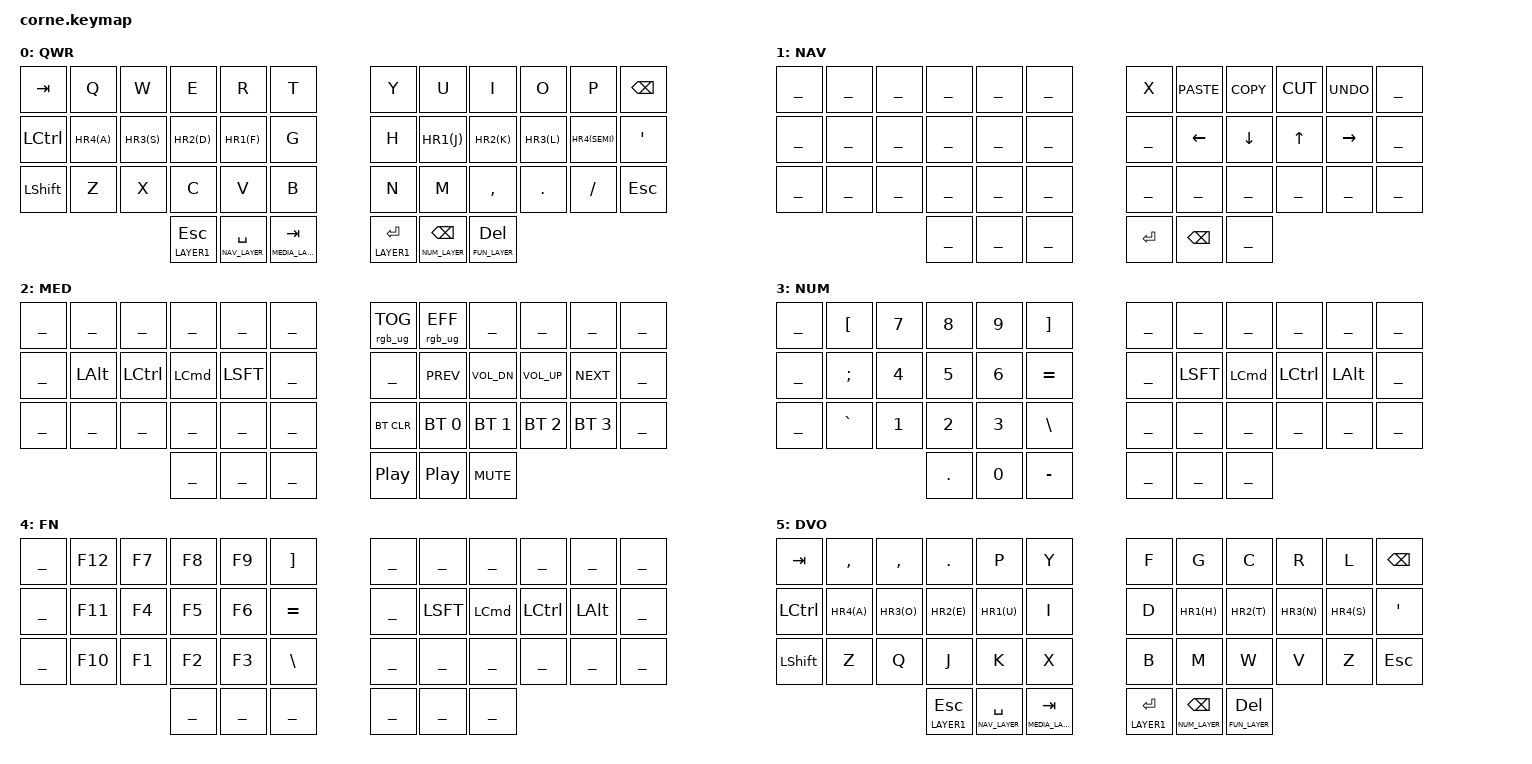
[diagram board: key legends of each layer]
/*
 * some ideas from https://github.com/rastasheep/zmk-config/blob/master/config/corne.keymap
 * and https://github.com/kkga/zmk-config-Corne-ish-Zen/blob/main/config/corne-ish_zen.keymap
 * https://github.com/manna-harbour/miryoku/tree/master/docs/reference
 * SPDX-License-Identifier: MIT
 */

#include <behaviors.dtsi>
#include <dt-bindings/zmk/keys.h>
#include <dt-bindings/zmk/bt.h>
#include <dt-bindings/zmk/rgb.h>
#include "helper.h"


&sk {
  release-after-ms = <STICKY_KEY_TIMEOUT>;
};

&caps_word {
  continue-list = <UNDERSCORE MINUS BACKSPACE N1 N2 N3 N4 N5 N6 N7 N8 N9 N0 KP_N1 KP_N2 KP_N3 KP_N4 KP_N5 KP_N6 KP_N7 KP_N8 KP_N9 KP_N0>;
};


#define HYP LS(LC(LA(LGUI)))
#define HYPER(key) LS(LC(LA(LG(key))))


#define LAYER0 0
#define LAYER1 1
#define LAYER2 2
#define LAYER3 3
#define LAYER4 4
#define LAYER5 5
#define LAYER6 6
#define LAYER7 7
#define LAYER8 8


#define QWERTY_LAYER 0
#define NAV_LAYER 1
#define MEDIA_LAYER 2
#define NUM_LAYER 3
#define FUN_LAYER 4

// thumbs
#define TH1 &mo_tap LAYER1 ESC
#define TH2 &mo_tap NAV_LAYER SPACE
#define TH3 &mo_tap MEDIA_LAYER TAB
#define TH4 &mo_tap LAYER1 RET  
#define TH5 &mo_tap NUM_LAYER BSPC
#define TH6 &mo_tap FUN_LAYER DEL


// HomeRowMod (right hand) - Shift / Cmd / Ctrl / Alt
#define HR1(KEY) &am LSFT KEY
#define HR2(KEY) &am LCMD KEY
#define HR3(KEY) &am LCTRL KEY
#define HR4(KEY) &am LALT KEY

#define HR1_ &kp LSFT 
#define HR2_ &kp LCMD 
#define HR3_ &kp LCTRL 
#define HR4_ &kp LALT 

/ {
    behaviors {
      am: alpha_mods {
          compatible = "zmk,behavior-hold-tap";
          label = "alpha mods";
          #binding-cells = <2>;
          tapping-term-ms = <240>;
          quick-tap-ms = <180>;
          flavor = "tap-preferred";
          bindings = <&kp>, <&kp>;
          // compatible = "zmk,behavior-hold-tap";
          // label = "POSITIONAL_HOLD_TAP";
          // #binding-cells = <2>;
          // flavor = "tap-unless-interrupted";
          // tapping-term-ms = <100>;                        // <---[[produces tap if held longer than tapping-term-ms]]
          // quick-tap-ms = <200>;
          // bindings = <&kp>, <&kp>;
          // hold-trigger-key-positions = <5 6 7 8 9 10>;    // <---[[right-hand keys]]
      };

      // Easy alt-tab with alt+space thumb using mod-morphs
      spctab: space_tab {
          compatible = "zmk,behavior-mod-morph";
          label = "SPC_TAB";
          #binding-cells = <0>;
          bindings = <&kp SPACE>, <&kp TAB>;
          mods = <MOD_LALT>;
      };

      skq: sticky_key_quick_release {
          compatible = "zmk,behavior-sticky-key";
          label = "STICKY_KEY_QUICK_RELEASE";
          #binding-cells = <1>;
          bindings = <&kp>;
          quick-release;
          release-after-ms = <STICKY_KEY_TIMEOUT>;
      };

      // Use hold-tap to enable rolling sticky keys:
      // https://github.com/zmkfirmware/zmk/issues/829#issuecomment-979864774
      nk: not_so_sticky_key {
          compatible = "zmk,behavior-hold-tap";
          label = "NOT_SO_STICKY_KEY";
          #binding-cells = <2>;
          tapping_term_ms = <240>;
          flavor = "tap-preferred";
          bindings = <&kp>, <&sk>;
      };

      // A hold-tap that activates without delay (like `&mo`)
      mo_tap: mo_with_tap {
          compatible = "zmk,behavior-hold-tap";
          label = "MO_WITH_TAP";
          #binding-cells = <2>;
          tapping_term_ms = <0>;
          retro-tap;
          flavor = "hold-preferred";
          bindings = <&mo>, <&kp>;
      };   
    };
        keymap {
                compatible = "zmk,keymap";
// Keyboard layout
// ╭─────────────┬─────────────┬─────────────┬─────────────┬─────────────┬─────────────╮   ╭─────────────┬─────────────┬─────────────┬─────────────┬─────────────┬─────────────╮
// ├─────────────┼─────────────┼─────────────┼─────────────┼─────────────┼─────────────┤   ├─────────────┼─────────────┼─────────────┼─────────────┼─────────────┼─────────────┤
// ├─────────────┼─────────────┼─────────────┼─────────────┼─────────────┼─────────────┤   ├─────────────┼─────────────┼─────────────┼─────────────┼─────────────┼─────────────┤
// ╰─────────────┴─────────────┴─────────────┼─────────────┼─────────────┼─────────────┤   ├─────────────┼─────────────┼─────────────┼─────────────┴─────────────┴─────────────╯
//                                           ╰─────────────┴─────────────┴─────────────╯   ╰─────────────┴─────────────┴─────────────╯



base_layer {
    label = "QWR";
    bindings = <
// ╭─────────────┬─────────────┬─────────────┬─────────────┬─────────────┬─────────────╮      ╭─────────────┬─────────────┬─────────────┬─────────────┬─────────────┬─────────────╮
     &kp TAB         &kp Q        &kp W          &kp E          &kp R         &kp T                &kp Y       &kp U          &kp I         &kp O          &kp P       &kp BSPC
// ├─────────────┼─────────────┼─────────────┼─────────────┼─────────────┼─────────────┤      ├─────────────┼─────────────┼─────────────┼─────────────┼─────────────┼─────────────┤
     &kp LCTRL      HR4(A)         HR3(S)        HR2(D)         HR1(F)        &kp G                &kp H         HR1(J)       HR2(K)         HR3(L)      HR4(SEMI)     &kp SQT
// ├─────────────┼─────────────┼─────────────┼─────────────┼─────────────┼─────────────┤      ├─────────────┼─────────────┼─────────────┼─────────────┼─────────────┼─────────────┤
     &kp LSHFT       &kp Z         &kp X         &kp C           &kp V       &kp B                 &kp N        &kp M        &kp COMMA      &kp DOT       &kp FSLH     &kp ESC
// ╰─────────────┴─────────────┴─────────────┴─────────────┼─────────────┼─────────────┤      ├─────────────┼─────────────┼─────────────┼─────────────┴─────────────┴─────────────╯
                                                TH1           TH2           TH3                  TH4          TH5            TH6        
//                                           ╰─────────────┴─────────────┴─────────────╯      ╰─────────────┴─────────────┴─────────────╯ 
    >;
};


nav_layer {
    label = "NAV";
    bindings = <

// Keyboard layout
// ╭─────────────┬─────────────┬─────────────┬─────────────┬─────────────┬─────────────╮   ╭─────────────┬─────────────┬─────────────┬─────────────┬─────────────┬─────────────╮
     ___            ___           ___           ___           ___           ___               &kp X        &kp K_PASTE    &kp K_COPY    &kp K_CUT    &kp K_UNDO     ___  
// ├─────────────┼─────────────┼─────────────┼─────────────┼─────────────┼─────────────┤   ├─────────────┼─────────────┼─────────────┼─────────────┼─────────────┼─────────────┤
     ___            ___           ___           ___           ___           ___               ___           &kp LEFT      &kp DOWN       &kp UP       &kp RIGHT     ___  
// ├─────────────┼─────────────┼─────────────┼─────────────┼─────────────┼─────────────┤   ├─────────────┼─────────────┼─────────────┼─────────────┼─────────────┼─────────────┤
     ___            ___           ___           ___           ___           ___               ___           ___           ___           ___           ___           ___  
// ╰─────────────┴─────────────┴─────────────┼─────────────┼─────────────┼─────────────┤   ├─────────────┼─────────────┼─────────────┼─────────────┴─────────────┴─────────────╯
                                                ___           ___           ___              &kp RET       &kp BSPC       ___     
//                                           ╰─────────────┴─────────────┴─────────────╯   ╰─────────────┴─────────────┴─────────────╯
    >;
};

media_layer {
    label = "MED";
    bindings = <

// Keyboard layout
// ╭─────────────┬─────────────┬─────────────┬─────────────┬─────────────┬─────────────╮   ╭─────────────┬─────────────┬─────────────┬─────────────┬─────────────┬─────────────╮
      ___            ___           ___           ___           ___           ___        &rgb_ug RGB_TOG &rgb_ug RGB_EFF    ___           ___           ___           ___  
// ├─────────────┼─────────────┼─────────────┼─────────────┼─────────────┼─────────────┤   ├─────────────┼─────────────┼─────────────┼─────────────┼─────────────┼─────────────┤
      ___            HR4_          HR3_          HR2_          HR1_          ___               ___       &kp C_PREV   &kp C_VOL_DN  &kp C_VOL_UP   &kp C_NEXT        ___  
// ├─────────────┼─────────────┼─────────────┼─────────────┼─────────────┼─────────────┤   ├─────────────┼─────────────┼─────────────┼─────────────┼─────────────┼─────────────┤
      ___            ___           ___           ___           ___           ___           &bt BT_CLR    &bt BT_SEL 0  &bt BT_SEL 1  &bt BT_SEL 2  &bt BT_SEL 3      ___  
// ╰─────────────┴─────────────┴─────────────┼─────────────┼─────────────┼─────────────┤   ├─────────────┼─────────────┼─────────────┼─────────────┴─────────────┴─────────────╯
                                                 ___           ___           ___             &kp C_PP     &kp C_PP     &kp C_MUTE                                   
//                                           ╰─────────────┴─────────────┴─────────────╯   ╰─────────────┴─────────────┴─────────────╯
    >;
};


num_layer {
    label = "NUM";
    bindings = <

// Keyboard layout
// ╭─────────────┬─────────────┬─────────────┬─────────────┬─────────────┬─────────────╮   ╭─────────────┬─────────────┬─────────────┬─────────────┬─────────────┬─────────────╮
     ___            &kp LBKT      &kp N7         &kp N8        &kp N9       &kp RBKT          ___           ___           ___           ___           ___           ___  
// ├─────────────┼─────────────┼─────────────┼─────────────┼─────────────┼─────────────┤   ├─────────────┼─────────────┼─────────────┼─────────────┼─────────────┼─────────────┤
     ___            &kp SEMI      &kp N4         &kp N5        &kp N6       &kp EQUAL         ___           HR1_          HR2_          HR3_          HR4_          ___  
// ├─────────────┼─────────────┼─────────────┼─────────────┼─────────────┼─────────────┤   ├─────────────┼─────────────┼─────────────┼─────────────┼─────────────┼─────────────┤
     ___            &kp GRAVE     &kp N1         &kp N2        &kp N3       &kp BSLH          ___           ___           ___           ___           ___           ___  
// ╰─────────────┴─────────────┴─────────────┼─────────────┼─────────────┼─────────────┤   ├─────────────┼─────────────┼─────────────┼─────────────┴─────────────┴─────────────╯
                                                 &kp DOT       &kp N0       &kp MINUS         ___           ___           ___     
//                                           ╰─────────────┴─────────────┴─────────────╯   ╰─────────────┴─────────────┴─────────────╯
    >;
};

fun_layer {
    label = "FN";
    bindings = <

// Keyboard layout
// ╭─────────────┬─────────────┬─────────────┬─────────────┬─────────────┬─────────────╮   ╭─────────────┬─────────────┬─────────────┬─────────────┬─────────────┬─────────────╮
     ___            &kp F12       &kp F7         &kp F8        &kp F9       &kp RBKT          ___           ___           ___           ___           ___           ___  
// ├─────────────┼─────────────┼─────────────┼─────────────┼─────────────┼─────────────┤   ├─────────────┼─────────────┼─────────────┼─────────────┼─────────────┼─────────────┤
     ___            &kp F11       &kp F4         &kp F5        &kp F6       &kp EQUAL         ___           HR1_          HR2_          HR3_          HR4_          ___  
// ├─────────────┼─────────────┼─────────────┼─────────────┼─────────────┼─────────────┤   ├─────────────┼─────────────┼─────────────┼─────────────┼─────────────┼─────────────┤
     ___            &kp F10       &kp F1         &kp F2        &kp F3       &kp BSLH          ___           ___           ___           ___           ___           ___  
// ╰─────────────┴─────────────┴─────────────┼─────────────┼─────────────┼─────────────┤   ├─────────────┼─────────────┼─────────────┼─────────────┴─────────────┴─────────────╯
                                                ___           ___           ___               ___           ___           ___     
//                                           ╰─────────────┴─────────────┴─────────────╯   ╰─────────────┴─────────────┴─────────────╯
    >;
};

dvo_layer {
    label = "DVO";
    bindings = <
// ╭─────────────┬─────────────┬─────────────┬─────────────┬─────────────┬─────────────╮      ╭─────────────┬─────────────┬─────────────┬─────────────┬─────────────┬─────────────╮
       &kp TAB      &kp COMMA    &kp COMMA      &kp DOT        &kp P         &kp Y                &kp F       &kp G          &kp C          &kp R         &kp L       &kp BSPC
// ├─────────────┼─────────────┼─────────────┼─────────────┼─────────────┼─────────────┤      ├─────────────┼─────────────┼─────────────┼─────────────┼─────────────┼─────────────┤
      &kp LCTRL      HR4(A)       HR3(O)        HR2(E)         HR1(U)        &kp I                &kp D         HR1(H)       HR2(T)         HR3(N)       HR4(S)        &kp SQT
// ├─────────────┼─────────────┼─────────────┼─────────────┼─────────────┼─────────────┤      ├─────────────┼─────────────┼─────────────┼─────────────┼─────────────┼─────────────┤
      &kp LSHFT      &kp Z         &kp Q         &kp J         &kp K         &kp X                &kp B        &kp M          &kp W         &kp V       &kp Z           &kp ESC
// ╰─────────────┴─────────────┴─────────────┴─────────────┼─────────────┼─────────────┤      ├─────────────┼─────────────┼─────────────┼─────────────┴─────────────┴─────────────╯
                                                   TH1           TH2           TH3                  TH4          TH5            TH6        
//                                           ╰─────────────┴─────────────┴─────────────╯      ╰─────────────┴─────────────┴─────────────╯ 
    >;
};


        };
};
